# PMM__Power_Management_System_2 register map
Vendor: Texas Instruments
Peripheral module from a debugger description file (folder msp430).
Registers are 16-bit, read-write, reset 0x0 unless marked. A register's access mark holds for its fields unless they carry their own. Offsets are as the file gives them; lines under a group give offsets from that group; [hi:lo] are bit positions; {n}, {i} and the like mark numbered series; 'fields as' and 'values as' point back to an identical list; <NAME> marks a mode.

## PMM_Power_Management_System
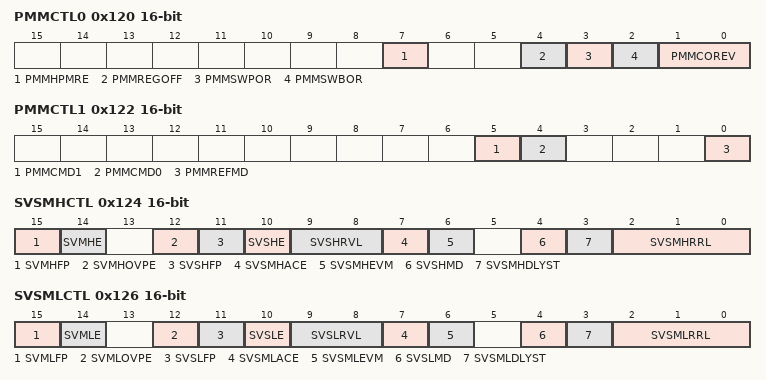
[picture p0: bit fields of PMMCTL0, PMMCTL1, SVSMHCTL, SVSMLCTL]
0x120 PMMCTL0 — PMM Control 0
  [7] PMMHPMRE — PMM Global High Power Module Request Enable
  [4] PMMREGOFF — PMM Turn Regulator off
  [3] PMMSWPOR — PMM Software POR
  [2] PMMSWBOR — PMM Software BOR
  [1:0] PMMCOREV — PMM Core Voltage Bit: 0
    0=PMM Core Voltage 0 (1.35V); 1=PMM Core Voltage 1 (1.55V); 2=PMM Core Voltage 2 (1.75V); 3=PMM Core Voltage 3 (1.85V)
0x122 PMMCTL1 — PMM Control 1
  [5] PMMCMD1 — PMM Voltage Regulator Current Mode Bit: 1
  [4] PMMCMD0 — PMM Voltage Regulator Current Mode Bit: 0
  [0] PMMREFMD — PMM Reference Mode
0x124 SVSMHCTL — SVS and SVM high side control register
  [15] SVMHFP — SVM high side full performace mode
  [14] SVMHE — SVM high side enable
  [12] SVMHOVPE — SVM high side over-voltage enable
  [11] SVSHFP — SVS high side full performace mode
  [10] SVSHE — SVS high side enable
  [9:8] SVSHRVL — SVS high side reset voltage level Bit: 0
    {v}=SVS high side Reset Release Voltage Level {v} (v=0..3)
  [7] SVSMHACE — SVS and SVM high side auto control enable
  [6] SVSMHEVM — SVS and SVM high side event mask
  [4] SVSHMD — SVS high side mode
  [3] SVSMHDLYST — SVS and SVM high side delay status
  [2:0] SVSMHRRL — SVS and SVM high side Reset Release Voltage Level Bit: 0
    {v}=SVS and SVM high side Reset Release Voltage Level {v} (v=0..7)
0x126 SVSMLCTL — SVS and SVM low side control register
  [15] SVMLFP — SVM low side full performace mode
  [14] SVMLE — SVM low side enable
  [12] SVMLOVPE — SVM low side over-voltage enable
  [11] SVSLFP — SVS low side full performace mode
  [10] SVSLE — SVS low side enable
  [9:8] SVSLRVL — SVS low side reset voltage level Bit: 0
    {v}=SVS low side Reset Release Voltage Level {v} (v=0..3)
  [7] SVSMLACE — SVS and SVM low side auto control enable
  [6] SVSMLEVM — SVS and SVM low side event mask
  [4] SVSLMD — SVS low side mode
  [3] SVSMLDLYST — SVS and SVM low side delay status
  [2:0] SVSMLRRL — SVS and SVM low side Reset Release Voltage Level Bit: 0
    {v}=SVS and SVM low side Reset Release Voltage Level {v} (v=0..7)
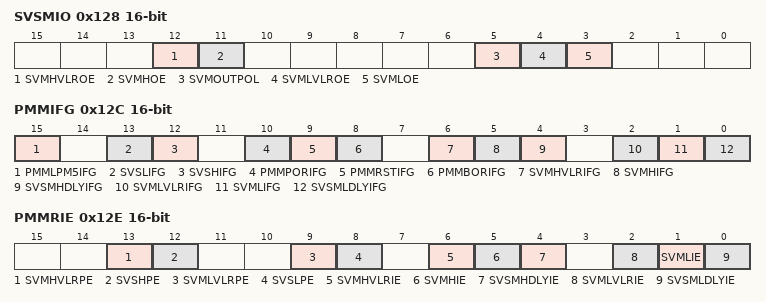
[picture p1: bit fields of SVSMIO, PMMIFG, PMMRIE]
0x128 SVSMIO — SVSIN and SVSOUT control register
  [12] SVMHVLROE — SVM high side voltage level reached output enable
  [11] SVMHOE — SVM high side output enable
  [5] SVMOUTPOL — SVMOUT pin polarity
  [4] SVMLVLROE — SVM low side voltage level reached output enable
  [3] SVMLOE — SVM low side output enable
0x12C PMMIFG — PMM Interrupt Flag
  [15] PMMLPM5IFG — LPM5 indication Flag
  [13] SVSLIFG — SVS high side interrupt flag
  [12] SVSHIFG — SVS low side interrupt flag
  [10] PMMPORIFG — PMM Software POR interrupt flag
  [9] PMMRSTIFG — PMM RESET pin interrupt flag
  [8] PMMBORIFG — PMM Software BOR interrupt flag
  [6] SVMHVLRIFG — SVM high side Voltage Level Reached interrupt flag
  [5] SVMHIFG — SVM high side interrupt flag
  [4] SVSMHDLYIFG — SVS and SVM high side Delay expired interrupt flag
  [2] SVMLVLRIFG — SVM low side Voltage Level Reached interrupt flag
  [1] SVMLIFG — SVM low side interrupt flag
  [0] SVSMLDLYIFG — SVS and SVM low side Delay expired interrupt flag
0x12E PMMRIE — PMM and RESET Interrupt Enable
  [13] SVMHVLRPE — SVM high side Voltage Level reached POR enable
  [12] SVSHPE — SVS high side POR enable
  [9] SVMLVLRPE — SVM low side Voltage Level reached POR enable
  [8] SVSLPE — SVS low side POR enable
  [6] SVMHVLRIE — SVM high side Voltage Level Reached interrupt enable
  [5] SVMHIE — SVM high side interrupt enable
  [4] SVSMHDLYIE — SVS and SVM high side Delay expired interrupt enable
  [2] SVMLVLRIE — SVM low side Voltage Level Reached interrupt enable
  [1] SVMLIE — SVM low side interrupt enable
  [0] SVSMLDLYIE — SVS and SVM low side Delay expired interrupt enable
0x130 PM5CTL0 — PMM Power Mode 5 Control Register 0
  [0] LOCKLPM5 — Lock I/O pin configuration upon entry/exit to/from LPM5
